VERSION ""

NS_ :

BS_:

BU_:

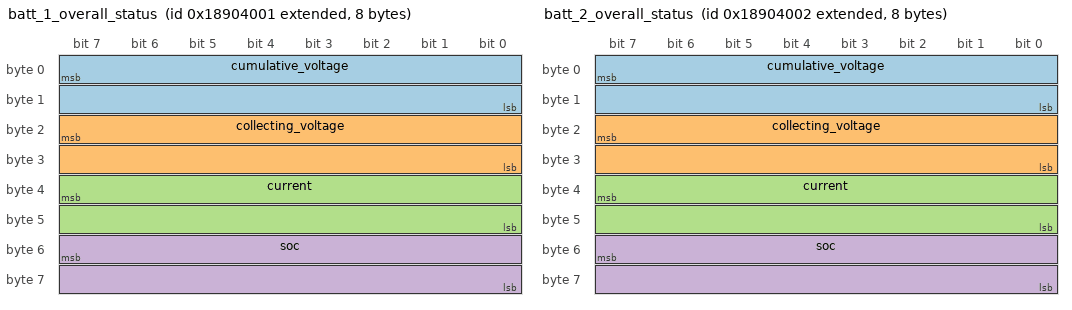
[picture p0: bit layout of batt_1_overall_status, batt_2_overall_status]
BO_ 2559590401 batt_1_overall_status: 8 Vector__XXX
	SG_ cumulative_voltage : 7|16@0+ (0.1,0) [0|60] "V" Vector__XXX
	SG_ collecting_voltage : 23|16@0+ (0.1,0) [0|60] "V" Vector__XXX
	SG_ current : 39|16@0+ (0.1,-3000) [0|60000] "A" Vector__XXX
	SG_ soc : 55|16@0+ (0.1,0) [0|1000] "%" Vector__XXX

BO_ 2559590402 batt_2_overall_status: 8 Vector__XXX
	SG_ cumulative_voltage : 7|16@0+ (0.1,0) [0|60] "V" Vector__XXX
	SG_ collecting_voltage : 23|16@0+ (0.1,0) [0|60] "V" Vector__XXX
	SG_ current : 39|16@0+ (0.1,-3000) [0|60000] "A" Vector__XXX
	SG_ soc : 55|16@0+ (0.1,0) [0|1000] "%" Vector__XXX

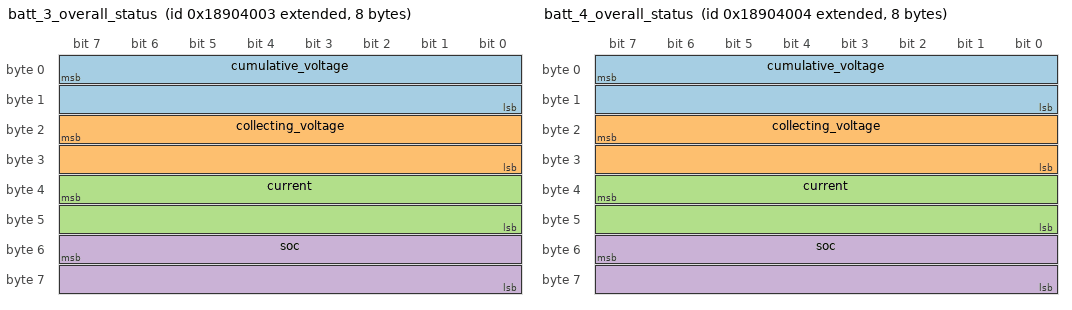
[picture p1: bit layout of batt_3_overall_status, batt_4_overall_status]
BO_ 2559590403 batt_3_overall_status: 8 Vector__XXX
	SG_ cumulative_voltage : 7|16@0+ (0.1,0) [0|60] "V" Vector__XXX
	SG_ collecting_voltage : 23|16@0+ (0.1,0) [0|60] "V" Vector__XXX
	SG_ current : 39|16@0+ (0.1,-3000) [0|60000] "A" Vector__XXX
	SG_ soc : 55|16@0+ (0.1,0) [0|1000] "%" Vector__XXX

BO_ 2559590404 batt_4_overall_status: 8 Vector__XXX
	SG_ cumulative_voltage : 7|16@0+ (0.1,0) [0|60] "V" Vector__XXX
	SG_ collecting_voltage : 23|16@0+ (0.1,0) [0|60] "V" Vector__XXX
	SG_ current : 39|16@0+ (0.1,-3000) [0|60000] "A" Vector__XXX
	SG_ soc : 55|16@0+ (0.1,0) [0|1000] "%" Vector__XXX

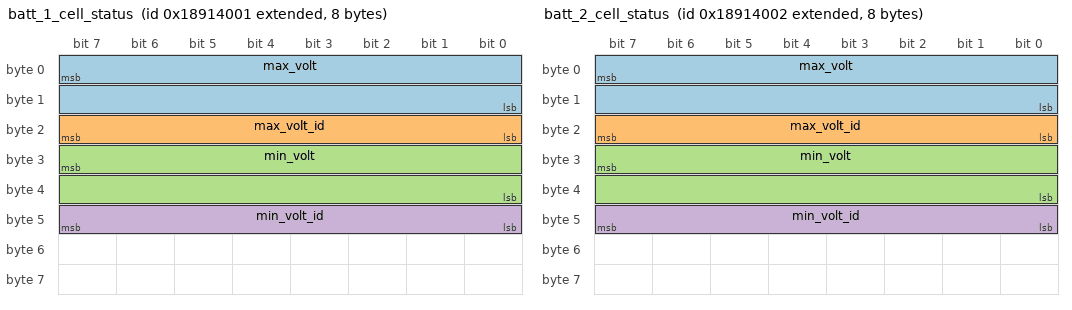
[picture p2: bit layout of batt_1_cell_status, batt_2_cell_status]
BO_ 2559655937 batt_1_cell_status: 8 Vector__XXX
	SG_ max_volt : 7|16@0+ (0.001,0) [0|60000] "V" Vector__XXX
	SG_ max_volt_id : 23|8@0+ (1,0) [0|63] "" Vector__XXX
	SG_ min_volt : 31|16@0+ (0.001,0) [0|60000] "V" Vector__XXX
	SG_ min_volt_id : 47|8@0+ (1,0) [0|63] "" Vector__XXX

BO_ 2559655938 batt_2_cell_status: 8 Vector__XXX
	SG_ max_volt : 7|16@0+ (0.001,0) [0|60000] "V" Vector__XXX
	SG_ max_volt_id : 23|8@0+ (1,0) [0|63] "" Vector__XXX
	SG_ min_volt : 31|16@0+ (0.001,0) [0|60000] "V" Vector__XXX
	SG_ min_volt_id : 47|8@0+ (1,0) [0|63] "" Vector__XXX

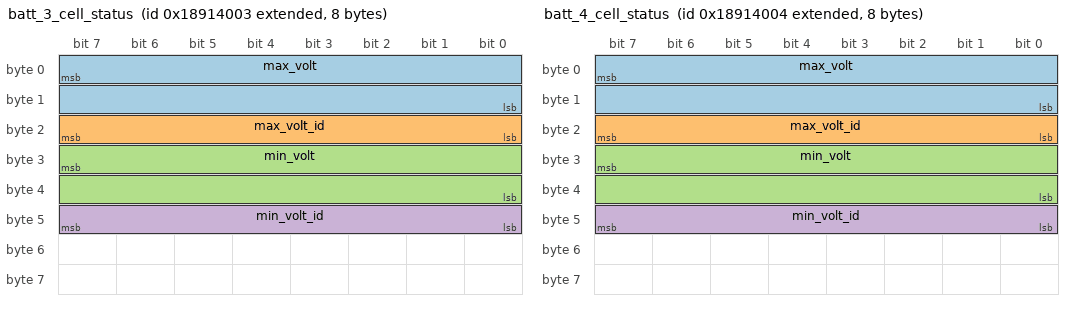
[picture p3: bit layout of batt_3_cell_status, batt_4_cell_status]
BO_ 2559655939 batt_3_cell_status: 8 Vector__XXX
	SG_ max_volt : 7|16@0+ (0.001,0) [0|60000] "V" Vector__XXX
	SG_ max_volt_id : 23|8@0+ (1,0) [0|63] "" Vector__XXX
	SG_ min_volt : 31|16@0+ (0.001,0) [0|60000] "V" Vector__XXX
	SG_ min_volt_id : 47|8@0+ (1,0) [0|63] "" Vector__XXX

BO_ 2559655940 batt_4_cell_status: 8 Vector__XXX
	SG_ max_volt : 7|16@0+ (0.001,0) [0|60000] "V" Vector__XXX
	SG_ max_volt_id : 23|8@0+ (1,0) [0|63] "" Vector__XXX
	SG_ min_volt : 31|16@0+ (0.001,0) [0|60000] "V" Vector__XXX
	SG_ min_volt_id : 47|8@0+ (1,0) [0|63] "" Vector__XXX

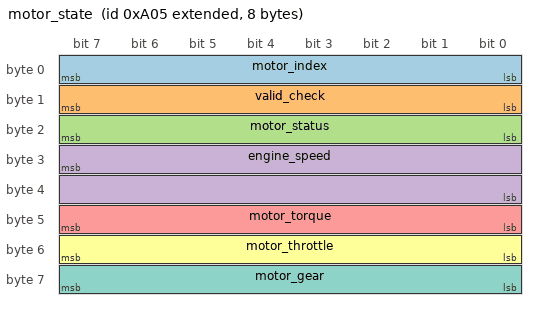
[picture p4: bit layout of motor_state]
BO_ 2147486213 motor_state: 8 Vector__XXX
	SG_ motor_index : 7|8@0+ (1,0) [0|0] "" Vector__XXX
	SG_ valid_check : 15|8@0+ (1,0) [0|0] "" Vector__XXX
	SG_ motor_status : 23|8@0+ (1,0) [0|0] "" Vector__XXX
	SG_ engine_speed : 31|16@0+ (0.25,0) [0|0] "RPM" Vector__XXX
	SG_ motor_torque : 47|8@0+ (1,0) [0|0] "" Vector__XXX
	SG_ motor_throttle : 55|8@0+ (1,0) [0|0] "" Vector__XXX
	SG_ motor_gear : 63|8@0+ (1,0) [0|0] "" Vector__XXX

CM_ BO_ 2559590401 "Battery 1 Overall Status";
CM_ BO_ 2559590402 "Battery 2 Overall Status";
CM_ BO_ 2559590403 "Battery 3 Overall Status";
CM_ BO_ 2559590404 "Battery 4 Overall Status";
CM_ BO_ 2559655937 "Battery 1 Cell Status";
CM_ BO_ 2559655938 "Battery 2 Cell Status";
CM_ BO_ 2559655939 "Battery 3 Cell Status";
CM_ BO_ 2559655940 "Battery 4 Cell Status";
CM_ BO_ 2147486213 "Motor state";
CM_ SG_ 2147486213 valid_check "ASCII 'V' for valid and 'N' for not valid";
BA_DEF_ SG_  "SPN" INT 0 524287;
BA_DEF_ BO_  "VFrameFormat" ENUM  "StandardCAN","ExtendedCAN","reserved","J1939PG";
BA_DEF_  "DatabaseVersion" STRING ;
BA_DEF_  "BusType" STRING ;
BA_DEF_  "ProtocolType" STRING ;
BA_DEF_  "DatabaseCompiler" STRING ;
BA_DEF_DEF_  "SPN" 0;
BA_DEF_DEF_  "VFrameFormat" "J1939PG";
BA_DEF_DEF_  "DatabaseVersion" "DEMO PLUS";
BA_DEF_DEF_  "BusType" "";
BA_DEF_DEF_  "ProtocolType" "";
BA_DEF_DEF_  "DatabaseCompiler" "";
BA_ "ProtocolType" "J1939";
BA_ "BusType" "CAN";
BA_ "DatabaseCompiler" "CSS ELECTRONICS (WWW.CSSELECTRONICS.COM)";
BA_ "DatabaseVersion" "1.0.0";
BA_ "SPN" SG_ 2364540158 EngineSpeed 190;
